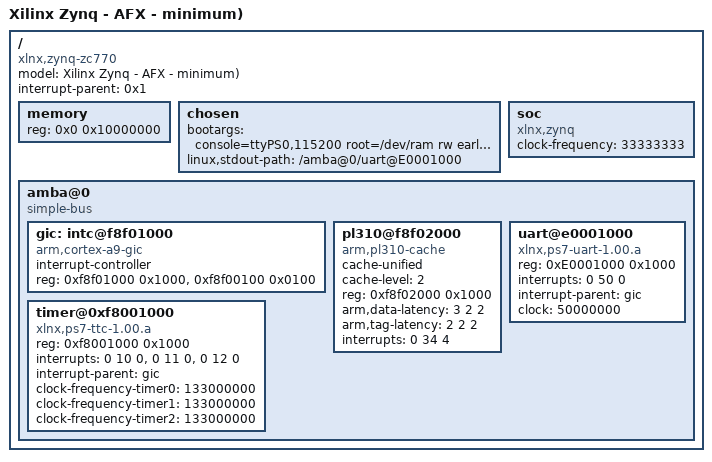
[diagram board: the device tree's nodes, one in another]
/dts-v1/;

/ {
	model = "Xilinx Zynq - AFX - minimum)";
	compatible = "xlnx,zynq-zc770";
	#address-cells = <0x1>;
	#size-cells = <0x1>;
	interrupt-parent = <0x1>;

	memory {
		device_type = "memory";
		reg = <0x0 0x10000000>;
	};

	chosen {
		bootargs = "console=ttyPS0,115200 root=/dev/ram rw earlyprintk ip=:::::eth0:dhcp";
		linux,stdout-path = "/amba@0/uart@E0001000";
	};

	soc {
		compatible = "xlnx,zynq";
		clock-frequency = <33333333>;
	};

	amba@0 {
		compatible = "simple-bus";
		#address-cells = <0x1>;
		#size-cells = <0x1>;
		ranges;

		gic: intc@f8f01000 {
			interrupt-controller;
			compatible = "arm,cortex-a9-gic";
			#interrupt-cells = <3>;
			reg = < 0xf8f01000 0x1000 >,
			      < 0xf8f00100 0x0100 >;
		};

		pl310@f8f02000 {
                        compatible = "arm,pl310-cache";
                        cache-unified;
                        cache-level = <2>;
                        reg = <0xf8f02000 0x1000>;
                        arm,data-latency = <3 2 2>;
                        arm,tag-latency = <2 2 2>;
                        interrupts = <0 34 4>;
                };

		uart@e0001000 {
			compatible = "xlnx,ps7-uart-1.00.a";
			reg = <0xE0001000 0x1000>;
			interrupts = <0 50 0>;
			interrupt-parent = <&gic>;
			clock = <50000000>;
		};

		timer@0xf8001000 {
			compatible = "xlnx,ps7-ttc-1.00.a";
			reg = <0xf8001000 0x1000>;
			interrupts = <0 10 0>,<0 11 0>,<0 12 0>;
			interrupt-parent = <&gic>;
			clock-frequency-timer0 = <133000000>;
			clock-frequency-timer1 = <133000000>;
			clock-frequency-timer2 = <133000000>;
		};

	};
};
